# RTC_SS register map
Vendor: Texas Instruments
Peripheral module from a debugger description file (folder am572x).
Registers are 32-bit, access per field, reset 0x0 unless marked. A register's access mark holds for its fields unless they carry their own. Offsets are as the file gives them; lines under a group give offsets from that group; [hi:lo] are bit positions; {n}, {i} and the like mark numbered series; 'fields as' and 'values as' point back to an identical list; <NAME> marks a mode.

## RTC_SS
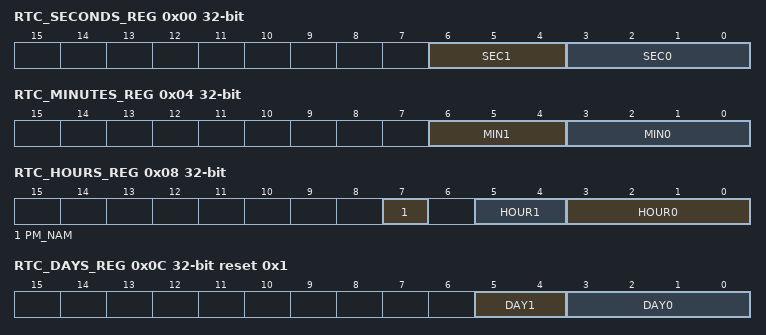
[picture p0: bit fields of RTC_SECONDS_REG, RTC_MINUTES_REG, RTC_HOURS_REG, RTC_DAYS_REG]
0x00 RTC_SECONDS_REG — Used to program the required seconds value of the current time. Seconds are stored in BCD format, the decimal numbers are encoded with their binary equivalent. That is, if seconds value is 45, then SEC0 = 5 and SEC1 = 4.
  [6:4] SEC1 rw — Second digit of seconds. Range is 0 to 5
  [3:0] SEC0 rw — First digit of seconds. Range is 0 to 9
0x04 RTC_MINUTES_REG — Used to program the required minutes value of the current time. Minutes are stored in BCD format, the decimal numbers are encoded with their binary equivalent. That is, if minutes value is 32, then MIN0 = 2 and MIN1 = 3.
  [6:4] MIN1 rw — Second digit of minutes Range is 0 to 5
  [3:0] MIN0 rw — First digit of minutes Range is 0 to 9
0x08 RTC_HOURS_REG — Used to program the hours value of the current time. Hours are stored in BCD format, the decimal numbers are encoded with their binary equivalent. That is, if hour is 18, then HOUR0 = 8 and HOUR1 = 1.
  [7] PM_NAM rw — Only used in PM_AM mode (otherwise 0) 0 = AM 1 = PM
  [5:4] HOUR1 rw — Second digit of hours Range is 0 to 2
  [3:0] HOUR0 rw — First digit of hours Range is 0 to 9
0x0C RTC_DAYS_REG reset 0x1 — Used to program the day of the month value of the current date. Days are stored as BCD format. In BCD format, the decimal numbers 0 through 9 are encoded with their binary equivalent. If the day value of the date is 28, DAY0 is set as 8 and DAY1 is set as 2.
  [5:4] DAY1 rw — Second digit of days Range from 0 to 3
  [3:0] DAY0 rw — First digit of days Range from 0 to 9
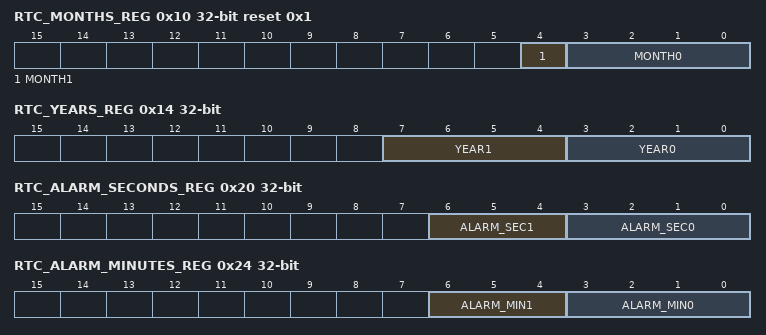
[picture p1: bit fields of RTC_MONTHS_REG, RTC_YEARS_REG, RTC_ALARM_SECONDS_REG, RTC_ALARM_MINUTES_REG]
0x10 RTC_MONTHS_REG reset 0x1 — MONTHS_REG is used to set the month in the year value of the current date. Months are stored as BCD format. In BCD format, the decimal numbers 0 through 9 are encoded with their binary equivalent.
  [4] MONTH1 rw — Second digit of months Range from 0 to 1
  [3:0] MONTH0 rw — First digit of months Range from 0 to 9
0x14 RTC_YEARS_REG — YEARS_REG is used to program the year value of the current date. The year value is represented by only the last two digits and is stored as BCD format. In BCD format, the decimal numbers 0 through 9 are encoded with their binary equivalent. The year 1979 is programmed as 79 with YEAR0 set as 9 and YEAR1 set as 7.
  [7:4] YEAR1 rw — Second digit of Years Range from 0 to 9
  [3:0] YEAR0 rw — First digit of Years Range from 0 to 9
0x18 RTC_WEEKS_REG — WEEKS_REG is used to program the day of the week value of the current date. The day of the week is stored as BCD format. In BCD format, the decimal numbers 0 through 9 are encoded with their binary equivalent.
  [2:0] WEEK rw — First digit of Days in a week Range from 0 (Sunday) to 6 (Saturday)
0x20 RTC_ALARM_SECONDS_REG — ALARM_SECONDS_REG is used to program the seconds value for the alarm interrupt. Seconds are stored as BCD format. In BCD format, the decimal numbers 0 through 9 are encoded with their binary equivalent.
  [6:4] ALARM_SEC1 rw — Second digit of seconds Range is 0 to 5
  [3:0] ALARM_SEC0 rw — First digit of seconds Range is 0 to 9
0x24 RTC_ALARM_MINUTES_REG — ALARM_MINUTES_REG is used to program the minute value for the alarm interrupt. Minutes are stored as BCD format. In BCD format, the decimal numbers 0 through 9 are encoded with their binary equivalent.
  [6:4] ALARM_MIN1 rw — Second digit of minutes Range is 0 to 5
  [3:0] ALARM_MIN0 rw — First digit of minutes Range is 0 to 9
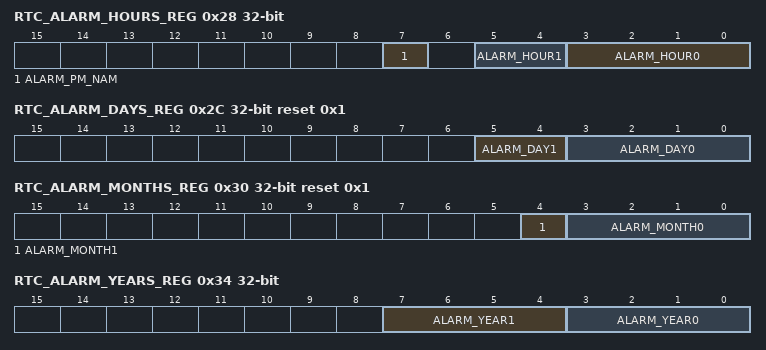
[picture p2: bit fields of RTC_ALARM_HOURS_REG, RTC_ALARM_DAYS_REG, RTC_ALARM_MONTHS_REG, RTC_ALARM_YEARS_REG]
0x28 RTC_ALARM_HOURS_REG — ALARM_HOURS_REG is used to program the hour value for the alarm interrupt. Hours are stored as BCD format. In BCD format, the decimal numbers 0 through 9 are encoded with their binary equivalent.
  [7] ALARM_PM_NAM rw — Only used in PM_AM mode (otherwise 0) 0 = AM 1 = PM
  [5:4] ALARM_HOUR1 rw — Second digit of hours. Range is 0 to 2
  [3:0] ALARM_HOUR0 rw — First digit of hours. Range is 0 to 9
0x2C RTC_ALARM_DAYS_REG reset 0x1 — ALARM_DAYS_REG is used to program the day of the month value for the alarm interrupt. Days are stored as BCD format. In BCD format, the decimal numbers 0 through 9 are encoded with their binary equivalent.
  [5:4] ALARM_DAY1 rw — Second digit for days. Range from 0 to 3
  [3:0] ALARM_DAY0 rw — First digit for days. Range from 0 to 9
0x30 RTC_ALARM_MONTHS_REG reset 0x1 — ALARM_MONTHS_REG is used to program the month in the year value for the alarm interrupt. The month is stored as BCD format. In BCD format, the decimal numbers 0 through 9 are encoded with their binary equivalent
  [4] ALARM_MONTH1 rw — Second digit of months. Range from 0 to 1
  [3:0] ALARM_MONTH0 rw — First digit of months. Range from 0 to 9
0x34 RTC_ALARM_YEARS_REG — ALARM_YEARS_REG is used to program the year for the alarm interrupt. Only the last two digits are used to represent the year and is stored as BCD format. In BCD format, the decimal numbers 0 through 9 are encoded with their binary equivalent
  [7:4] ALARM_YEAR1 rw — Second digit of years. Range from 0 to 9
  [3:0] ALARM_YEAR0 rw — First digit of years. Range from 0 to 9
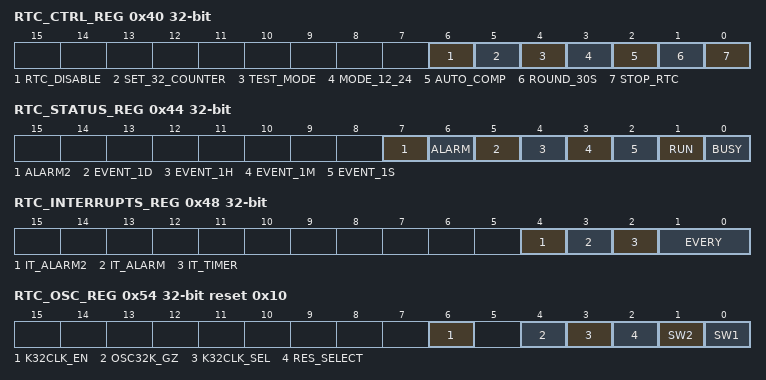
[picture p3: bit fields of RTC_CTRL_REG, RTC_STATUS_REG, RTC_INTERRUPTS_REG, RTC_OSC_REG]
0x40 RTC_CTRL_REG — CTRL_REG contains the controls to enable/disable RTC.
  [6] RTC_DISABLE rw — 0: RTC enable 1: RTC disable (no 32-kHz clock)
  [5] SET_32_COUNTER rw — 0: No action 1: Set the 32-kHz counter with comp_reg value
  [4] TEST_MODE rw — 0: Functional mode 1: Test mode (Auto compensation is enabled when the 32-kHz counter reaches its end.)
  [3] MODE_12_24 rw — 0: 24-hour mode 1: 12-hour mode (PM-AM mode)
  [2] AUTO_COMP rw — 0: No auto compensation 1: Auto compensation enabled
  [1] ROUND_30S rw — 0: No update 1: When a 1 is written, the time is rounded to the closest minute.
  [0] STOP_RTC rw — 0: RTC is frozen. 1: RTC is running.
0x44 RTC_STATUS_REG — RTC STATUS_REG contains bits that signal the status of interrupts, events to the processor. Status for the alarm interrupt and timer events are notified by the register.
  [7] ALARM2 rw — Indicates that an alarm2 interrupt has been generated. Software must wait 31 µs before it clears this status to allow PMIC_PWR_ENABLE 1 - 0 transmission.
  [6] ALARM rw — Indicates that an alarm interrupt has been generated. Writing 1 to the bit clears the interrupt.
  [5] EVENT_1D ro — One day has occurred.
  [4] EVENT_1H ro — One hour has occurred.
  [3] EVENT_1M ro — One minute has occurred.
  [2] EVENT_1S ro — One second has occurred.
  [1] RUN ro — 0: RTC is frozen. 1: RTC is running.
  [0] BUSY ro — 0: Updating event in more than 15 µs. 1: Updating event. This bit will give the status of RTC module. The time and alarm registers can be modified only when this bit is 0.
0x48 RTC_INTERRUPTS_REG — INTERRUPTS_REG is used to enable or disable RTC from generating interrupts. The timer interrupt and alarm interrupt can be controlled using this register.
  [4] IT_ALARM2 rw — Enable one interrupt when the alarm value is reached (TC ALARM2 registers) by the TC registers
  [3] IT_ALARM rw — Enable one interrupt when the alarm value is reached (TC ALARM registers) by the TC registers
  [2] IT_TIMER rw — Enable periodic interrupt 0 = interrupt disabled 1 = interrupt enabled
  [1:0] EVERY rw — Interrupt period: 0 - every second 1 - every minute 2 - every hour 3 - every day
0x4C RTC_COMP_LSB_REG — COMP_LSB_REG is used to program the LSB value of the 32-kHz periods to be added to the 32-kHz counter every hour. This is used to compensate the oscillator drift. The COMP_LSB_REG works with the compensation (MSB) register (COMP_MSB_REG). The AUTOCOMP bit in the control register (CTRL_REG) must be enabled for compensation to OCCUR.
  [7:0] RTC_COMP_LSB rw — Indicates number of 32-kHz periods to be added into the 32-kHz counter every hour.
0x50 RTC_COMP_MSB_REG — COMP_MSB_REG is used to program the MSB value of the 32-kHz periods to be added to the 32-kHz counter every hour. This is used to compensate the oscillator drift. The COMP_MSB_REG works with the compensation (LSB) register (COMP_LSB_REG) to set the hourly oscillator compensation value. The AUTOCOMP bit in the control register (CTRL_REG) must be enabled for compensation to OCCUR.
  [7:0] RTC_COMP_MSB rw — Indicates number of 32-kHz periods to be added into the 32-kHz counter every hour
0x54 RTC_OSC_REG reset 0x10 — OSC_REG is used to program the oscillator resistance value, and to select and enable the clock source.
  [6] K32CLK_EN rw — 32-kHz clock enable post clock mux of RTC_32K_AUX_CLK and RTC_32K_CLK.
  [4] OSC32K_GZ rw — Disable the oscillator and applies high impedance to the output. 0: Enable 1: Disabled and high impedance
  [3] K32CLK_SEL rw — 32-kHz clock source select. 0: Selects internal clock source, namely RTC_32K_AUX_CLK, from PRCM. 1: Selects external clock source namely RTC_32K_CLK, from the 32-kHz Oscillator.
  [2] RES_SELECT rw — External feedback resistor selection. 0: Internal 1: External
  [1] SW2 rw — Inverter size adjustment.
  [0] SW1 rw — Inverter size adjustment.
0x60 RTC_SCRATCH0_REG rw — Used to hold some required values for the RTC register.
  [31:0] RTCSCRATCH0 — Scratch registers, available to program.
0x64 RTC_SCRATCH1_REG rw — Used to hold some required values for the RTC register.
  [31:0] RTCSCRATCH1 — Scratch registers, available to program
0x68 RTC_SCRATCH2_REG rw — Used to hold some required values for the RTC register.
  [31:0] RTCSCRATCH2 — Scratch registers, available to program.
0x6C RTC_KICK0_REG wo — The KICK0 register allows writing to unlock the kick0 data. To disable RTC register write protection, the value of 83E7 0B13h must be written to KICK0, followed by the value of 95A4 F1E0h written to KICK1. RTC register write protection is enabled when any value is written to KICK0
  [31:0] KICK0 — Kick0 data.
0x70 RTC_KICK1_REG wo — Kick1 data. The KICK1 register allows writing to unlock the kick1 data and the kicker mechanism to write to other registers. To disable RTC register write protection, the value of 83E7 0B13h must be written to KICK0, followed by the value of 95A4 F1E0h written to KICK1.
  [31:0] KICK1 — Kick1 data.
0x74 RTC_REVISION_REG ro reset not defined
  [31:0] REVISION — IP Revision
0x78 RTC_SYSCONFIG_REG reset 0x2
  [1:0] IDLEMODE rw — Configuration of the local target state management mode, By definition target can handle read/write transaction as long as it is out of IDLE state.
    0=IP_0 (Force-idle mode: local target's idle state follows (acknowledges) the system's idle requests unconditionally, i.e., regardless of the IP module's internal requirements; Backup mode, for debug only.); 1=No-idle mode: local target never enters idle state, Backup mode, for debug only; 2=IP_IP_(IRQ-_2 (Smart-idle mode: local target's state eventually follows (acknowledges) the system's idle requests, depending on the IP module's internal requirements, IP module shall not generate (IRQ- or DMArequest- related) wakeup events.); 3=IP_IP_(IRQ-_IP_3 (Smart-idle wakeup-capable mode: local target's idle state eventually follows (acknowledges the system's idle requests, depending on the IP module's internal requirements, IP module may generate (IRQ- or DMA-request-related) wakeup events when in idle state, Mode is only relevant if the appropriate IP module 'swakeup' output(s) is (are) implemented.)
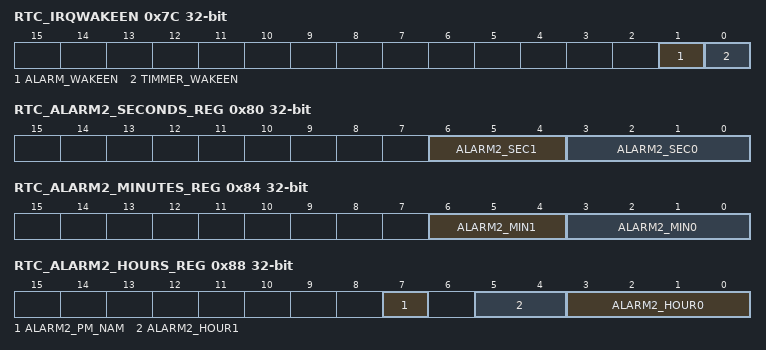
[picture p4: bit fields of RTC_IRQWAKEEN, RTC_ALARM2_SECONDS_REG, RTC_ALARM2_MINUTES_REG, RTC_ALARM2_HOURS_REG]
0x7C RTC_IRQWAKEEN rw
  [1] ALARM_WAKEEN — Wakeup generation for event Alarm 0: Wakeup disabled 1: Wakeup enable
  [0] TIMMER_WAKEEN — Wakeup generation for event Timer 0: Wakeup disabled 1: Wakeup enable Timer wakeup should not get used.
0x80 RTC_ALARM2_SECONDS_REG — ALARM2_SECONDS_REG is used to program the seconds value of the ALARM2 time
  [6:4] ALARM2_SEC1 rw — Second digit of seconds Range is 0 to 5
  [3:0] ALARM2_SEC0 rw — First digit of seconds Range is 0 to 9
0x84 RTC_ALARM2_MINUTES_REG
  [6:4] ALARM2_MIN1 rw — Second digit of minutes Range is 0 to 5
  [3:0] ALARM2_MIN0 rw — First digit of minutes Range is 0 to 9
0x88 RTC_ALARM2_HOURS_REG
  [7] ALARM2_PM_NAM rw — Only used in PM_AM mode (otherwise 0) 0 = AM 1 = PM
  [5:4] ALARM2_HOUR1 rw — Second digit of hours Range is 0 to 2
  [3:0] ALARM2_HOUR0 rw — First digit of hours Range is 0 to 9
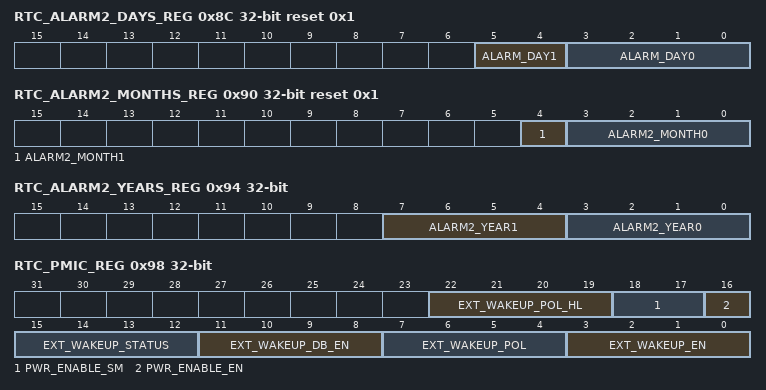
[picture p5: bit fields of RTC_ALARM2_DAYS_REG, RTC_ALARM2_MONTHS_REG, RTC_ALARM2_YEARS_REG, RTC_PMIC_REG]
0x8C RTC_ALARM2_DAYS_REG reset 0x1
  [5:4] ALARM_DAY1 rw — Second digit for days Range from 0 to 3
  [3:0] ALARM_DAY0 rw — First digit for days Range from 0 to 9
0x90 RTC_ALARM2_MONTHS_REG reset 0x1
  [4] ALARM2_MONTH1 rw — Second digit of months Range from 0 to 1
  [3:0] ALARM2_MONTH0 rw — First digit of months Range from 0 to 9
0x94 RTC_ALARM2_YEARS_REG
  [7:4] ALARM2_YEAR1 rw — Second digit of Years Range from 0 to 9
  [3:0] ALARM2_YEAR0 rw — First digit of Years Range from 0 to 9
0x98 RTC_PMIC_REG rw
  [22:19] EXT_WAKEUP_POL_HL — External wakeup inputs polarity enable for Active High and Active Low 0: Disabled 1: Enabled, Active High and Active Low EXT_WAKEUP_POL_HL[0] controls ext_wakeup0; EXT_WAKEUP_POL_HL[N] controls ext_wakeup n ; Note when enabled EXT_WAKEUP_POL_HL overrides EXT_WAKEUP_POL
  [18:17] PWR_ENABLE_SM — Power State Machine state 00 = Idle/Default 01 = Shutdown (ALARM2 and pwr_enable enable is set, note 31uS latency from ALARM2 event.) 10 = Time based wakeup (ALARM status is set) 11 = External event based wakeup (one or more bit set in EXT_WAKEUP_STATUS)
  [16] PWR_ENABLE_EN — pwr_enable enable 0: Disable When Disabled, PMIC_PWR_ENABLE will always be drive 1, ON state 1: Enable When enabled: PMIC_PWR_ENABLE will be controlled by ext_wakeup 3:0 , alarm , and alarm2. ON - OFF (Turn OFF) By ALARM2 event OFF - ON (TURN ON) By ALARM event OR ext_wakeup n event
  [15:12] EXT_WAKEUP_STATUS — External wakeup status 0: External wakeup event has not occurred 1: External wakeup event has occurred Wrt 1 to Clear EXT_WAKEUP_STATUS[0] status of ext_wakeup0 event EXT_WAKEUP_STATUS[N] status of ext_wakeup n event. SW must clear the events before PMIC_PWR_ENABLE can go from 1 - 0.
  [11:8] EXT_WAKEUP_DB_EN — External wakeup debounce enabled 0: Disable 1: Enable EXT_WAKEUP_DB_EN[0] controls ext_wakeup0; EXT_WAKEUP_DB_EN[N] controls ext_wakeup n ; When enabled RTL_DEBOUNCE_REG defines the debounce time.
  [7:4] EXT_WAKEUP_POL — External wakeup inputs polarity 0: Active High 1: Active Low EXT_WAKEUP_POL[0] controls ext_wakeup0; EXT_WAKEUP_POL[N] controls ext_wakeup n ;
  [3:0] EXT_WAKEUP_EN — Enable External wakeup inputs 0: Ext Wakeup disabled 1: Ext Wakeup enable EXT_WAKEUP_EN[0] controls ext_wakeup0; EXT_WAKEUP_EN[N] controls ext_wakeup n ;
0x9C RTC_RTL_DEBOUNCE_REG rw
  [7:0] DEBOUNCE_REG — Debounce time, see for details.
